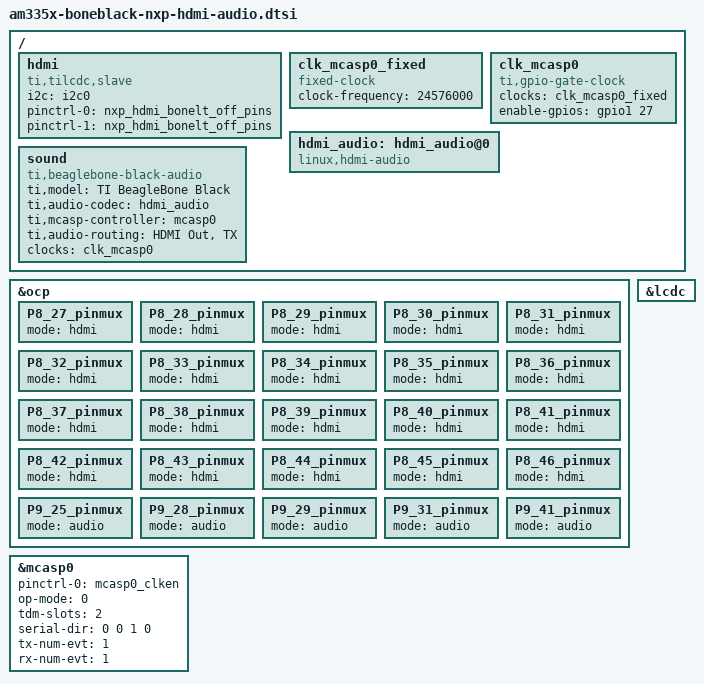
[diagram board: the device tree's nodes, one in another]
/*
 * Copyright (C) 2012 Texas Instruments Incorporated - http://www.ti.com/
 *
 * This program is free software; you can redistribute it and/or modify
 * it under the terms of the GNU General Public License version 2 as
 * published by the Free Software Foundation.
 */

&ocp {
	/* hdmi */
	P8_27_pinmux {
		mode = "hdmi";
	};
	P8_28_pinmux {
		mode = "hdmi";
	};
	P8_29_pinmux {
		mode = "hdmi";
	};
	P8_30_pinmux {
		mode = "hdmi";
	};
	P8_31_pinmux {
		mode = "hdmi";
	};
	P8_32_pinmux {
		mode = "hdmi";
	};
	P8_33_pinmux {
		mode = "hdmi";
	};
	P8_34_pinmux {
		mode = "hdmi";
	};
	P8_35_pinmux {
		mode = "hdmi";
	};
	P8_36_pinmux {
		mode = "hdmi";
	};
	P8_37_pinmux {
		mode = "hdmi";
	};
	P8_38_pinmux {
		mode = "hdmi";
	};
	P8_39_pinmux {
		mode = "hdmi";
	};
	P8_40_pinmux {
		mode = "hdmi";
	};
	P8_41_pinmux {
		mode = "hdmi";
	};
	P8_42_pinmux {
		mode = "hdmi";
	};
	P8_43_pinmux {
		mode = "hdmi";
	};
	P8_44_pinmux {
		mode = "hdmi";
	};
	P8_45_pinmux {
		mode = "hdmi";
	};
	P8_46_pinmux {
		mode = "hdmi";
	};
	/* audio */
	P9_25_pinmux {
		mode = "audio";
	};
	P9_28_pinmux {
		mode = "audio";
	};
	P9_29_pinmux {
		mode = "audio";
	};
	P9_31_pinmux {
		mode = "audio";
	};
	P9_41_pinmux {
		mode = "audio";
	};
};

&lcdc {
	status = "okay";
};

&mcasp0	{
	pinctrl-names = "default", "sleep";
	pinctrl-0 = <&mcasp0_clken>;
	/* pinctrl-0 = <&mcasp0_pins>; */
	/* pinctrl-1 = <&mcasp0_pins_sleep>; */
	status = "okay";
	op-mode = <0>;	/* MCASP_IIS_MODE */
	tdm-slots = <2>;
	serial-dir = <	/* 0: INACTIVE, 1: TX, 2: RX */
			0 0 1 0
		>;
	tx-num-evt = <1>;
	rx-num-evt = <1>;
};

/ {
	hdmi {
		compatible = "ti,tilcdc,slave";
		i2c = <&i2c0>;
		pinctrl-names = "default", "off";
		/* pinctrl-0 = <&nxp_hdmi_bonelt_pins>; */
		pinctrl-0 = <&nxp_hdmi_bonelt_off_pins>;
		pinctrl-1 = <&nxp_hdmi_bonelt_off_pins>;
		status = "okay";
	};

	clk_mcasp0_fixed: clk_mcasp0_fixed {
	      #clock-cells = <0>;
	      compatible = "fixed-clock";
	      clock-frequency = <24576000>;
	};

	clk_mcasp0: clk_mcasp0 {
	      #clock-cells = <0>;
	      compatible = "ti,gpio-gate-clock";
	      clocks = <&clk_mcasp0_fixed>;
	      enable-gpios = <&gpio1 27 0>; /* BeagleBone Black Clk enable on GPIO1_27 */
	};

	hdmi_audio: hdmi_audio@0 {
	       compatible = "linux,hdmi-audio";
	       status = "okay";
	};

	sound {
		compatible = "ti,beaglebone-black-audio";
		ti,model = "TI BeagleBone Black";
		ti,audio-codec = <&hdmi_audio>;
		ti,mcasp-controller = <&mcasp0>;
		ti,audio-routing =
			"HDMI Out",	"TX";
		clocks = <&clk_mcasp0>;
		clock-names = "mclk";
	};
};
